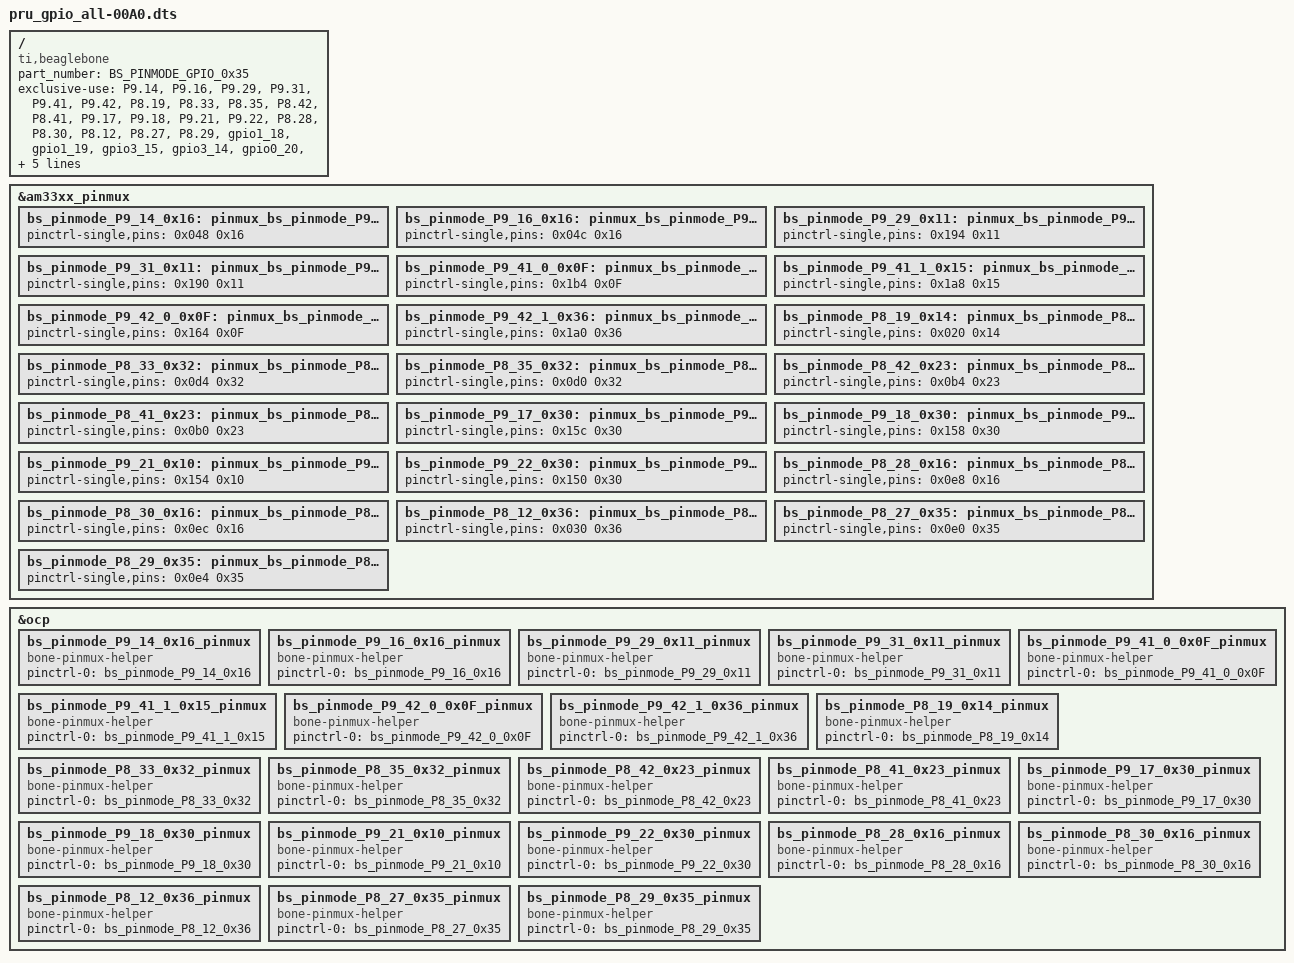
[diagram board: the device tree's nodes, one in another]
/*
 * This is a template-generated file from BoneScript
 */

/dts-v1/;
/plugin/;

/{
    compatible = "ti,beaglebone", "ti,beaglebone-black";
    part_number = "BS_PINMODE_GPIO_0x35";

    // P9.14, ehrpwm1a - AIN1 
    // P9.16, ehrpwm1b - AIN2
    // P9.29, ehrpwm0b - BIN1
    // P9.31, ehrpwm0a - BIN2
    // P9.41, pr1_pru0_pru_r3x_6 - nSleep
    // P9.42, pr1_pru0_pru_r3x_4 - nFault
    
    // P8.19, ehrpwm2a - SPK
    
    // P8.33, eQEP1B - L-ENC_B
    // P8.35, eQEP1A - L-ENC_A
    // P8.42, eQEP2B - R-ENC_B
    // P8.41, eQEP2A - R-ENC_A
    
    // P9.17, SPI0_CS0
    // P9.18, SPI0_DI
    // P9.21, SPI0_DO
    // P9.22, SPI0_CLK
    // P8.28, pr1_pru1_pru_r3x_10 - INT1
    // P8.30, pr1_pru1_pru_r3x_11 - INT2
    
    // P8.12, pr1_pru1_pru_r3x_12 - LED 1
    // P8.27, pr1_pru1_pru_r3x_8 - LED 2
    // P8.29, pr1_pru1_pru_r3x_9 - LED 3
    
    exclusive-use =
        "P9.14",
        "P9.16",
        "P9.29",
        "P9.31",
        "P9.41",
        "P9.42",
        "P8.19",
        "P8.33",
        "P8.35",
        "P8.42",
        "P8.41",
        "P9.17",
        "P9.18",
        "P9.21",
        "P9.22",
        "P8.28",
        "P8.30",
        "P8.12",
        "P8.27",
        "P8.29",
        "gpio1_18",
        "gpio1_19",
        "gpio3_15",
        "gpio3_14",
        "gpio0_20",
        "gpio3_20",
        "gpio0_7",
        "gpio3_18",
        "gpio0_22",
        "gpio0_9",
        "gpio0_8",
        "gpio2_11",
        "gpio2_10",
        "gpio0_5",
        "gpio0_4",
        "gpio0_3",
        "gpio0_2",
        "gpio2_24",
        "gpio2_25",
        "gpio1_12",
        "gpio2_22",
        "gpio2_23";
        
    fragment@0 {
        target = <&am33xx_pinmux>;
        __overlay__ {
            bs_pinmode_P9_14_0x16: pinmux_bs_pinmode_P9_14_0x16 {
                pinctrl-single,pins = <0x048 0x16>;
            };
            bs_pinmode_P9_16_0x16: pinmux_bs_pinmode_P9_16_0x16 {
                pinctrl-single,pins = <0x04c 0x16>;
            };
            bs_pinmode_P9_29_0x11: pinmux_bs_pinmode_P9_29_0x11 {
                pinctrl-single,pins = <0x194 0x11>;
            };
            bs_pinmode_P9_31_0x11: pinmux_bs_pinmode_P9_31_0x11 {
                pinctrl-single,pins = <0x190 0x11>;
            };
            bs_pinmode_P9_41_0_0x0F: pinmux_bs_pinmode_P9_41_0_0x0F {
                pinctrl-single,pins = <0x1b4 0x0F>;
            };
            bs_pinmode_P9_41_1_0x15: pinmux_bs_pinmode_P9_41_1_0x15 {
                pinctrl-single,pins = <0x1a8 0x15>;
            };
            bs_pinmode_P9_42_0_0x0F: pinmux_bs_pinmode_P9_42_0_0x0F {
                pinctrl-single,pins = <0x164 0x0F>;
            };
            bs_pinmode_P9_42_1_0x36: pinmux_bs_pinmode_P9_42_1_0x36 {
                pinctrl-single,pins = <0x1a0 0x36>;
            };
            bs_pinmode_P8_19_0x14: pinmux_bs_pinmode_P8_19_0x14 {
                pinctrl-single,pins = <0x020 0x14>;
            };
            bs_pinmode_P8_33_0x32: pinmux_bs_pinmode_P8_33_0x12 {
                pinctrl-single,pins = <0x0d4 0x32>;
            };
            bs_pinmode_P8_35_0x32: pinmux_bs_pinmode_P8_35_0x12 {
                pinctrl-single,pins = <0x0d0 0x32>;
            };
            bs_pinmode_P8_42_0x23: pinmux_bs_pinmode_P8_42_0x23 {
                pinctrl-single,pins = <0x0b4 0x23>;
            };
            bs_pinmode_P8_41_0x23: pinmux_bs_pinmode_P8_41_0x23 {
                pinctrl-single,pins = <0x0b0 0x23>;
            };
            bs_pinmode_P9_17_0x30: pinmux_bs_pinmode_P9_17_0x30 {
                pinctrl-single,pins = <0x15c 0x30>;
            };
            bs_pinmode_P9_18_0x30: pinmux_bs_pinmode_P9_18_0x30 {
                pinctrl-single,pins = <0x158 0x30>;
            };
            bs_pinmode_P9_21_0x10: pinmux_bs_pinmode_P9_21_0x10 {
                pinctrl-single,pins = <0x154 0x10>;
            };
            bs_pinmode_P9_22_0x30: pinmux_bs_pinmode_P9_22_0x30 {
                pinctrl-single,pins = <0x150 0x30>;
            }; 
            bs_pinmode_P8_28_0x16: pinmux_bs_pinmode_P8_28_0x16 {
                pinctrl-single,pins = <0x0e8 0x16>;
            };
            bs_pinmode_P8_30_0x16: pinmux_bs_pinmode_P8_30_0x16 {
                pinctrl-single,pins = <0x0ec 0x16>;
            };
            bs_pinmode_P8_12_0x36: pinmux_bs_pinmode_P8_12_0x36 {
                pinctrl-single,pins = <0x030 0x36>;
            };
            bs_pinmode_P8_27_0x35: pinmux_bs_pinmode_P8_27_0x35 {
                pinctrl-single,pins = <0x0e0 0x35>;
            };
            bs_pinmode_P8_29_0x35: pinmux_bs_pinmode_P8_29_0x35 {
                pinctrl-single,pins = <0x0e4 0x35>;
            };
        };
    };

    fragment@1 {
        target = <&ocp>;
        __overlay__ {
            bs_pinmode_P9_14_0x16_pinmux {
                compatible = "bone-pinmux-helper";
                status = "okay";
                pinctrl-names = "default";
                pinctrl-0 = <&bs_pinmode_P9_14_0x16>;
            };
            bs_pinmode_P9_16_0x16_pinmux {
                compatible = "bone-pinmux-helper";
                status = "okay";
                pinctrl-names = "default";
                pinctrl-0 = <&bs_pinmode_P9_16_0x16>;
            };
            bs_pinmode_P9_29_0x11_pinmux {
                compatible = "bone-pinmux-helper";
                status = "okay";
                pinctrl-names = "default";
                pinctrl-0 = <&bs_pinmode_P9_29_0x11>;
            };
            bs_pinmode_P9_31_0x11_pinmux {
                compatible = "bone-pinmux-helper";
                status = "okay";
                pinctrl-names = "default";
                pinctrl-0 = <&bs_pinmode_P9_31_0x11>;
            };
            bs_pinmode_P9_41_0_0x0F_pinmux {
                compatible = "bone-pinmux-helper";
                status = "okay";
                pinctrl-names = "default";
                pinctrl-0 = <&bs_pinmode_P9_41_0_0x0F>;
            };
            bs_pinmode_P9_41_1_0x15_pinmux {
                compatible = "bone-pinmux-helper";
                status = "okay";
                pinctrl-names = "default";
                pinctrl-0 = <&bs_pinmode_P9_41_1_0x15>;
            };
            bs_pinmode_P9_42_0_0x0F_pinmux {
                compatible = "bone-pinmux-helper";
                status = "okay";
                pinctrl-names = "default";
                pinctrl-0 = <&bs_pinmode_P9_42_0_0x0F>;
            };
            bs_pinmode_P9_42_1_0x36_pinmux {
                compatible = "bone-pinmux-helper";
                status = "okay";
                pinctrl-names = "default";
                pinctrl-0 = <&bs_pinmode_P9_42_1_0x36>;
            };
            bs_pinmode_P8_19_0x14_pinmux {
                compatible = "bone-pinmux-helper";
                status = "okay";
                pinctrl-names = "default";
                pinctrl-0 = <&bs_pinmode_P8_19_0x14>;
            };
            bs_pinmode_P8_33_0x32_pinmux {
                compatible = "bone-pinmux-helper";
                status = "okay";
                pinctrl-names = "default";
                pinctrl-0 = <&bs_pinmode_P8_33_0x32>;
            };
            bs_pinmode_P8_35_0x32_pinmux {
                compatible = "bone-pinmux-helper";
                status = "okay";
                pinctrl-names = "default";
                pinctrl-0 = <&bs_pinmode_P8_35_0x32>;
            };
            bs_pinmode_P8_42_0x23_pinmux {
                compatible = "bone-pinmux-helper";
                status = "okay";
                pinctrl-names = "default";
                pinctrl-0 = <&bs_pinmode_P8_42_0x23>;
            };
            bs_pinmode_P8_41_0x23_pinmux {
                compatible = "bone-pinmux-helper";
                status = "okay";
                pinctrl-names = "default";
                pinctrl-0 = <&bs_pinmode_P8_41_0x23>;
            };
            bs_pinmode_P9_17_0x30_pinmux {
                compatible = "bone-pinmux-helper";
                status = "okay";
                pinctrl-names = "default";
                pinctrl-0 = <&bs_pinmode_P9_17_0x30>;
            };
            bs_pinmode_P9_18_0x30_pinmux {
                compatible = "bone-pinmux-helper";
                status = "okay";
                pinctrl-names = "default";
                pinctrl-0 = <&bs_pinmode_P9_18_0x30>;
            };
            bs_pinmode_P9_21_0x10_pinmux {
                compatible = "bone-pinmux-helper";
                status = "okay";
                pinctrl-names = "default";
                pinctrl-0 = <&bs_pinmode_P9_21_0x10>;
            };
            bs_pinmode_P9_22_0x30_pinmux {
                compatible = "bone-pinmux-helper";
                status = "okay";
                pinctrl-names = "default";
                pinctrl-0 = <&bs_pinmode_P9_22_0x30>;
            };
            bs_pinmode_P8_28_0x16_pinmux {
                compatible = "bone-pinmux-helper";
                status = "okay";
                pinctrl-names = "default";
                pinctrl-0 = <&bs_pinmode_P8_28_0x16>;
            };
            bs_pinmode_P8_30_0x16_pinmux {
                compatible = "bone-pinmux-helper";
                status = "okay";
                pinctrl-names = "default";
                pinctrl-0 = <&bs_pinmode_P8_30_0x16>;
            };
            bs_pinmode_P8_12_0x36_pinmux {
                compatible = "bone-pinmux-helper";
                status = "okay";
                pinctrl-names = "default";
                pinctrl-0 = <&bs_pinmode_P8_12_0x36>;
            };
            bs_pinmode_P8_27_0x35_pinmux {
                compatible = "bone-pinmux-helper";
                status = "okay";
                pinctrl-names = "default";
                pinctrl-0 = <&bs_pinmode_P8_27_0x35>;
            };
            bs_pinmode_P8_29_0x35_pinmux {
                compatible = "bone-pinmux-helper";
                status = "okay";
                pinctrl-names = "default";
                pinctrl-0 = <&bs_pinmode_P8_29_0x35>;
            };
        };
    };
};
